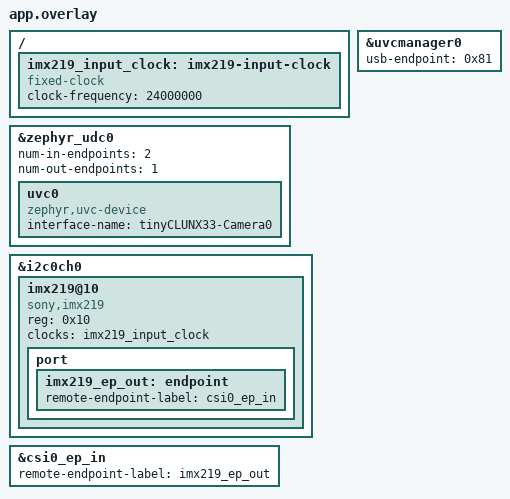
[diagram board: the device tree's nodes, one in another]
/*
 * Copyright (c) 2025 tinyVision.ai Inc.
 *
 * SPDX-License-Identifier: Apache-2.0
 */

#include <riscv/tinyvision/from_csi0_to_stats0.dtsi>
#include <riscv/tinyvision/from_csi0_to_debayer0.dtsi>
#include <riscv/tinyvision/from_debayer0_to_uvcmanager0.dtsi>

/* USB interfaces */

&zephyr_udc0 {
	num-in-endpoints = <2>;
	num-out-endpoints = <1>;
	status = "okay";

	uvc0: uvc0 {
		compatible = "zephyr,uvc-device";
		interface-name = "tinyCLUNX33-Camera0";
	};
};

&uvcmanager0 {
	usb-endpoint = <0x81>;
};

/* Camera 0 config */

/ {
	imx219_input_clock: imx219-input-clock {
		compatible = "fixed-clock";
		clock-frequency = <24000000>;
		#clock-cells = <0>;
	};
};

&i2c0ch0 {
	imx219@10 {
		compatible = "sony,imx219";
		reg = <0x10>;
		clocks = <&imx219_input_clock>;

		port {
			imx219_ep_out: endpoint {
				remote-endpoint-label = "csi0_ep_in";
			};
		};
	};
};

&csi0_ep_in {
	remote-endpoint-label = "imx219_ep_out";
};
